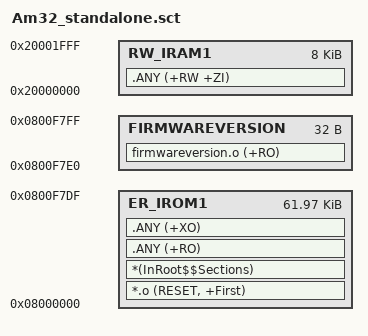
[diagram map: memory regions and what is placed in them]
; GD32F350x8 direct-SWD layout. Build with VECT_TAB_OFFSET=0.

LR_IROM1 0x08000000 0x0000F7E0  {
  ER_IROM1 0x08000000 0x0000F7E0  {
   *.o (RESET, +First)
   *(InRoot$$Sections)
   .ANY (+RO)
   .ANY (+XO)
  }
  RW_IRAM1 0x20000000 0x00002000  {
   .ANY (+RW +ZI)
  }
}
LR_FIRMWAREVERSION 0x0800F7E0 0x00000020{
	FIRMWAREVERSION 0x0800F7E0 0x00000020{
	firmwareversion.o (+RO)
	}
}
